# GD32W515Px register map
File version: 1.0
CPU: CM33 r0p0, little endian, MPU, FPU, 4 interrupt priority bits
Registers are 32-bit, read-write, reset 0x0 unless marked. A register's access mark holds for its fields unless they carry their own. Offsets are from the block's base; [hi:lo] are bit positions; {n}, {i} and the like mark numbered series.

## DCB — Debug Control Block
Base 0xE000EE08
0x00 DSCSR — Debug Security Control and Status Register
  [16] CDS — Current domain Secure

## CRC — cyclic redundancy check calculation unit
Base 0x40023000
Same registers: SEC_CRC 0x50023000
0x00 DATA reset 0xFFFFFFFF
  [31:0] DATA — CRC calculation result bits
0x04 FDATA — Free data register
  [7:0] FDATA — Free Data Register bits
0x08 CTL — Control register
  [0] RST — reset the CRC_DATA register

## TRNG — Ture random number generator
Base 0x4C060800
Same registers: SEC_TRNG 0x5C060800
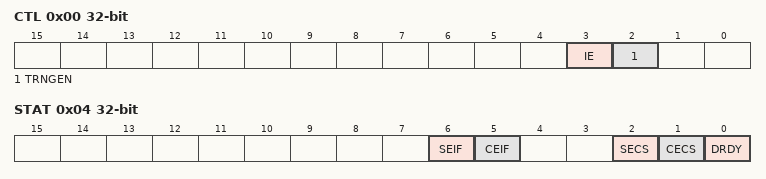
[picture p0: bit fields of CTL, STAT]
0x00 CTL — Control register
  [3] IE — Interrupt bit
  [2] TRNGEN — TRNG enable bit
0x04 STAT access per field — Status register
  [6] SEIF rw — Seed error interrupt flag
  [5] CEIF rw — Clock error interrupt flag
  [2] SECS ro — Seed error current status
  [1] CECS ro — Clock error current status
  [0] DRDY ro — Random data ready status bit
0x08 DATA ro
  [31:0] TRNDATA — 32-bit random data

## DBG — Debug support
Base 0xE0044000
0x00 ID ro — ID code register
  [31:0] ID_CODE — DBG ID code register
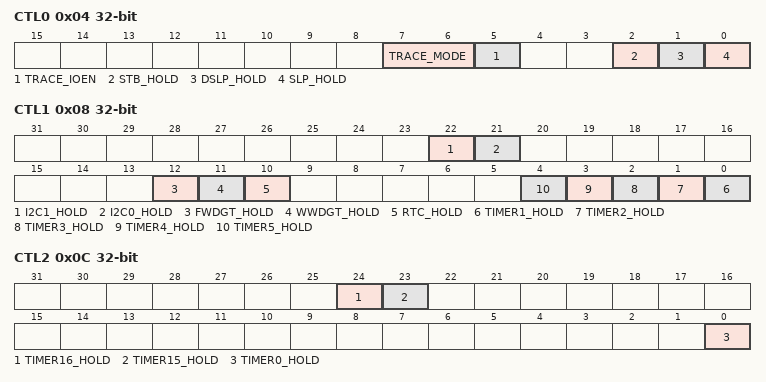
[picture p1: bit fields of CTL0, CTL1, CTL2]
0x04 CTL0 — Control register 0
  [7:6] TRACE_MODE — Trace pin allocation mode
  [5] TRACE_IOEN — Trace pin allocation enable
  [2] STB_HOLD — Standby mode hold register
  [1] DSLP_HOLD — Deep-sleep mode hold register
  [0] SLP_HOLD — Sleep mode hold register
0x08 CTL1 — Control register 1
  [22] I2C1_HOLD, [21] I2C0_HOLD, [12] FWDGT_HOLD, [11] WWDGT_HOLD, [10] RTC_HOLD, [n-1] TIMER{n}_HOLD (n=1..5)
0x0C CTL2 — Control register 2
  [24] TIMER16_HOLD, [23] TIMER15_HOLD, [0] TIMER0_HOLD

## EFUSE
Base 0x40022800
Same registers: SEC_EFUSE 0x50022800
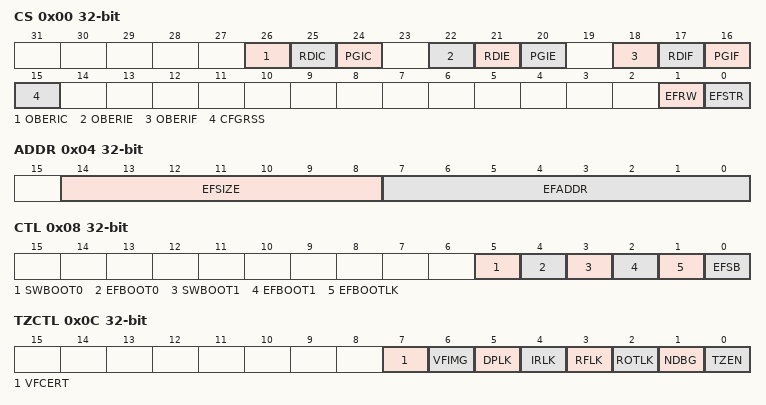
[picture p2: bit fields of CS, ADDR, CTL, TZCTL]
0x00 CS access per field — Control and status register
  [26] OBERIC rw — Clear bit for overstep boundary error interrupt flag
  [25] RDIC rw — Clear bit for read operation completed interrupt flag
  [24] PGIC rw — Clear bit for program operation completed interrupt flag
  [22] OBERIE rw — Enable bit for overstep boundary error interrupt
  [21] RDIE rw — Enable bit for read operation completed interrupt
  [20] PGIE rw — Enable bit for program operation completed interrupt
  [18] OBERIF ro — Overstep boundary error flag
  [17] RDIF ro — Read operation complete flag
  [16] PGIF ro — Program operation completed flag
  [15] CFGRSS ro — EFUSE_IAK_RSS register contribute configuer
  [1] EFRW rw — The selection of efuse operation
  [0] EFSTR rw — Start efuse operation
0x04 ADDR — Address register
  [14:8] EFSIZE — Read or write efuse data size
  [7:0] EFADDR — Read or write efuse data start address
0x08 CTL — Control register
  [5] SWBOOT0 — Efuse boot 0 bit enable
  [4] EFBOOT0 — Efuse boot0
  [3] SWBOOT1 — Efuse boot 1 bit enable
  [2] EFBOOT1 — Efuse boot1
  [1] EFBOOTLK — EFUSE_CTL register bit[5:2] lock bit
  [0] EFSB — Boot from Secure boot
0x0C TZCTL — Trustzone control register
  [7] VFCERT — Verify firmware certificate
  [6] VFIMG — Verify firmware image
  [5] DPLK — EFUSE_DP register lock bit
  [4] IRLK — EFUSE_IAK_RSS register lock bit
  [3] RFLK — EFUSE_RF_DATA register lock bit
  [2] ROTLK — EFUSE_ROTPK_KEY register lock bit
  [1] NDBG — Debugging permission setting
  [0] TZEN — Trust zone enable bit
0x10 FP_CTL — Flash protection control register
  [7:0] FP — Efuse flash protection value
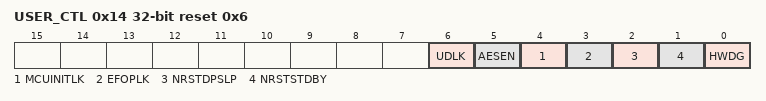
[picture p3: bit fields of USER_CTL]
0x14 USER_CTL ro reset 0x6 — User byte control register
  [6] UDLK — EFUSE_USER_DATA register lock bit
  [5] AESEN — Lock EFUSE_AES_KEY register and enable AES decrypt function
  [4] MCUINITLK — EFUSE_MCU_INIT_DATA register lock bit
  [3] EFOPLK — EFUSE_FP_CTL and EFUSE_USER_CTL register lock bit
  [2] NRSTDPSLP — Reset option of entry deep sleep mode
  [1] NRSTSTDBY — Reset option of entry standby mode
  [0] HWDG — Free watchdog timer selection
{0x18+4i} MCU_INIT_DATA{i} (i=0..2) — Mcu initialization data register{i}
  [31:0] INITDATA — Efuse mcu_init value
{0x24+4i} AES_KEY{i} (i=0..3) — Firmware AES key register {i}
  [31:0] AESKEY — Efuse AES key value.
{0x34+4i} ROTPK_KEY{i} (i=0..7) — RoTPK key register {i}
  [31:0] RKEY — Efuse RoTPK or its hash value.
0x54 DP0 — Debug password register 0
  [31:0] DP — Efuse Debug password value
0x58 DP1 — Debug password register 1
  [31:0] DP — Efuse Debug password value
{0x5C+4i} IAK_RSS{i} (i=0..15) — IAK key or RSS register {i}
  [31:0] IAKRSS — Efuse IAK/RSS value
{0x9C+4i} PUID{i} ro (i=0..3) — Product UID register {i}
  [31:0] UID — Efuse MCU UID value.
{0xAC+4i} HUK_KEY{i} ro (i=0..3) — HUK key register {i}
  [31:0] HKEY — Efuse HUK value
0xBC RF_DATA0 — RF data register
  [31:0] HKEY — Efuse HUK value
{0xBC+4i} RF_DATA{i} (i=1..11) — RF data register {i}
  [31:0] RFDATA — Efuse RF data value
{0xEC+4i} USER_DATA{i} (i=0..7) — User data register {i}
  [31:0] USERDATA — Efuse USER_DATA value.
0x118 PRE_TZEN — EFUSE Pre-TZEN register
  [0] STZEN — Enable Trustzone function by software
0x120 TZ_BOOT_ADDR ro — TrustZone boot address register
  [31:0] TZBOOTADDR — Boot from the address when TrustZone is enabled
0x124 NTZ_BOOT_ADDR ro — No-TrustZone boot address register
  [31:0] NTZBOOTADDR — Boot from the address when TrustZone is disabled
